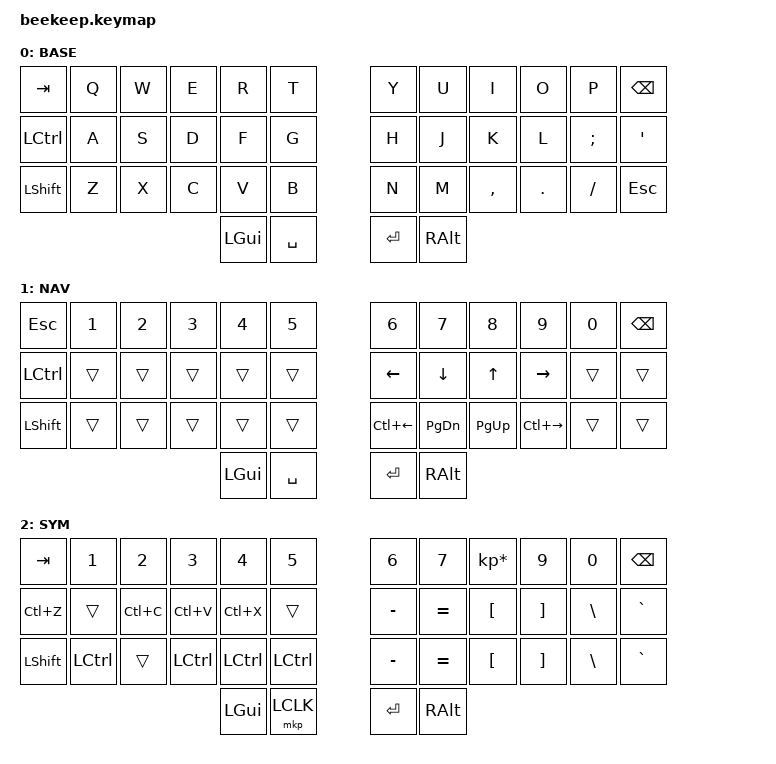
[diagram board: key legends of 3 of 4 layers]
/*
 * Copyright (c) 2020 The ZMK Contributors
 *
 * SPDX-License-Identifier: MIT
 */

#include <behaviors.dtsi>
#include <dt-bindings/zmk/keys.h>
#include <dt-bindings/zmk/bt.h>
#include <dt-bindings/zmk/outputs.h>
#include <dt-bindings/zmk/mouse.h>

/ {
    conditional_layers {
        compatible = "zmk,conditional-layers";
        tri_layer {
            if-layers = <1 2>;
            then-layer = <3>;
        };
    };

    keymap {
        compatible = "zmk,keymap";

        base {
            display-name = "BASE";
            bindings = <
                &kp TAB   &kp Q &kp W &kp E &kp R &kp T   &kp Y &kp U  &kp I     &kp O   &kp P    &kp BSPC
                &kp LCTRL &kp A &kp S &kp D &kp F &kp G   &kp H &kp J  &kp K     &kp L   &kp SEMI &kp SQT
                &kp LSHFT &kp Z &kp X &kp C &kp V &kp B   &kp N &kp M  &kp COMMA &kp DOT &kp FSLH &kp ESC
                                &kp LGUI &kp SPACE      &kp RET &kp RALT
            >;
        };

        nav {
            display-name = "NAV";
            bindings = <
                &kp ESC 
                  &kp N1 &kp N2 &kp N3 &kp N4 &kp N5   &kp N6   &kp N7    &kp N8    &kp N9    &kp N0 &kp BSPC
                &kp LCTRL &trans &trans &trans &trans &trans   &kp LEFT &kp DOWN  &kp UP    &kp RIGHT &trans &trans
                &kp LSHFT &trans &trans &trans &trans &trans   &kp LC(LEFT) &kp PG_DN &kp PG_UP &kp LC(RIGHT) &trans &trans
                                 &kp LGUI &kp SPACE        &kp RET &kp RALT
            >;
        };

        sym {
            display-name = "SYM";
            bindings = <
                &kp TAB   &kp N1 &kp N2 &kp N3 &kp N4 &kp N5   &kp N6    &kp N7    &kp KP_MULTIPLY &kp N9    &kp N0   &kp BSPC
                &kp LC(Z) &trans &kp LC(C) &kp LC(V) &kp LC(X) &trans   &kp MINUS &kp EQUAL &kp LBKT        &kp RBKT  &kp BSLH &kp GRAVE
                &kp LSHFT &kp LCTRL &trans &kp LCTRL &kp LCTRL &kp LCTRL &kp MINUS &kp EQUAL &kp LBKT        &kp RBKT  &kp BSLH &kp GRAVE
                                 &kp LGUI &mkp LCLK        &kp RET &kp RALT
            >;
        };

        adj {
            display-name = "ADJ";
            bindings = <
                &kp TAB   &studio_unlock &kp F7 &kp F8 &kp F9 &kp F12   &kp C_VOL_DN &kp C_MUTE &kp C_VOL_UP &trans &trans &kp BSPC
                &kp LCTRL &studio_unlock &kp F4 &kp F5 &kp F6 &kp F11   &trans       &trans     &trans       &trans &trans &trans
                &kp LSHFT &kp F1 &kp F2 &kp F3 &kp F10 &trans   &trans       &trans     &trans       &trans &trans &kp LGUI
                                 &kp LANG2 &kp SPACE        &kp RET &kp RALT &kp LANG1
            >;
        };
    };
};
